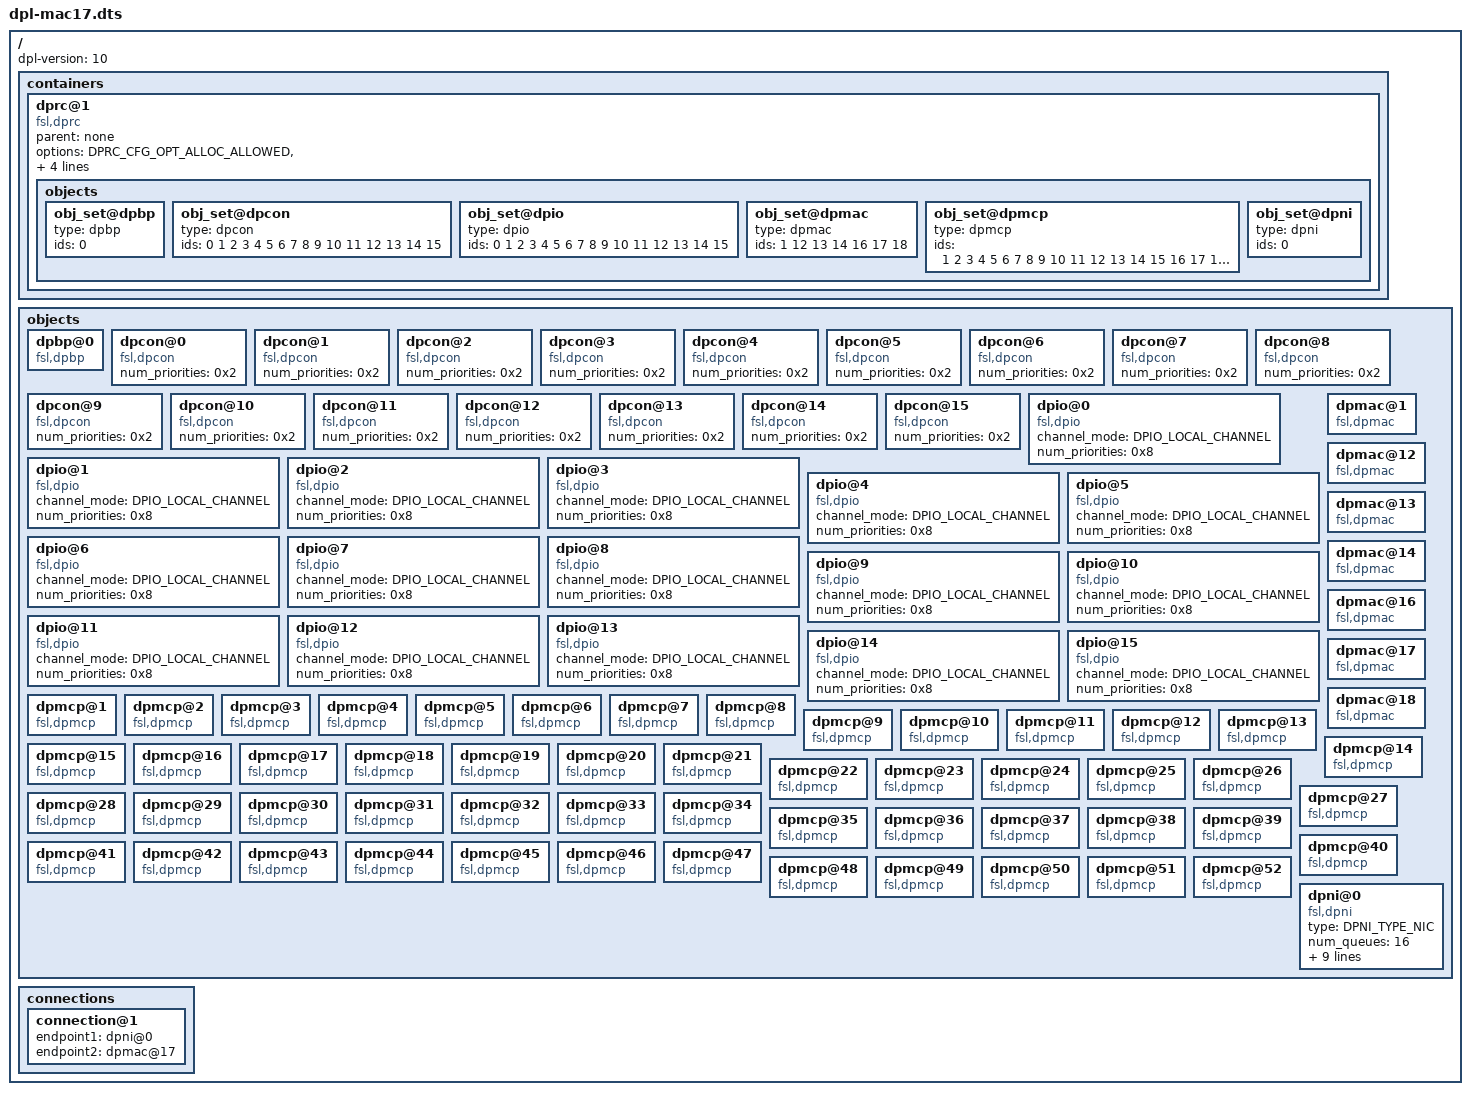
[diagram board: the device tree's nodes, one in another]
/* SPDX-License-Identifier: BSD-3-Clause */
/*
 * Copyright (c) 2024 TQ-Systems GmbH <oss@ew.tq-group.com>
 * D-82229 Seefeld, Germany.
 * Author: Gregor Herburger
 *
 */

/dts-v1/;
/ {
	dpl-version = <10>;
	/*****************************************************************
	 * Containers
	 *****************************************************************/
	containers {

		dprc@1 {
			compatible = "fsl,dprc";
			parent = "none";
			options = "DPRC_CFG_OPT_ALLOC_ALLOWED",
				  "DPRC_CFG_OPT_IRQ_CFG_ALLOWED",
				  "DPRC_CFG_OPT_OBJ_CREATE_ALLOWED",
				  "DPRC_CFG_OPT_SPAWN_ALLOWED",
				  "DPRC_CFG_OPT_TOPOLOGY_CHANGES_ALLOWED";

			objects {

				/* -------------- DPBPs --------------*/
				obj_set@dpbp {
					type = "dpbp";
					ids = <0 >;
				};

				/* -------------- DPCONs --------------*/
				obj_set@dpcon {
					type = "dpcon";
					ids = <0 1 2 3 4 5 6 7 8 9 10 11 12 13 14 15 >;
				};

				/* -------------- DPIOs --------------*/
				obj_set@dpio {
					type = "dpio";
					ids = <0 1 2 3 4 5 6 7 8 9 10 11 12 13 14 15 >;
				};

				/* -------------- DPMACs --------------*/
				obj_set@dpmac {
					type = "dpmac";
					ids = <1 12 13 14 16 17 18 >;
				};

				/* -------------- DPMCPs --------------*/
				obj_set@dpmcp {
					type = "dpmcp";
					ids = <
						1 2 3 4 5 6 7 8 9 10 11 12 13 14 15
						16 17 18 19 20 21 22 23 24 25 26 27
						28 29 30 31 32 33 34 35 36 37 38 39
						40 41 42 43 44 45 46 47 48 49 50 51 52
					      >;
				};

				/* -------------- DPNIs --------------*/
				obj_set@dpni {
					type = "dpni";
					ids = <0 >;
				};
			};
		};
	};

	/*****************************************************************
	 * Objects
	 *****************************************************************/
	objects {

		dpbp@0 {
			compatible = "fsl,dpbp";
		};

		dpcon@0 {
			compatible = "fsl,dpcon";
			num_priorities = <0x2>;
		};

		dpcon@1 {
			compatible = "fsl,dpcon";
			num_priorities = <0x2>;
		};

		dpcon@2 {
			compatible = "fsl,dpcon";
			num_priorities = <0x2>;
		};

		dpcon@3 {
			compatible = "fsl,dpcon";
			num_priorities = <0x2>;
		};

		dpcon@4 {
			compatible = "fsl,dpcon";
			num_priorities = <0x2>;
		};

		dpcon@5 {
			compatible = "fsl,dpcon";
			num_priorities = <0x2>;
		};

		dpcon@6 {
			compatible = "fsl,dpcon";
			num_priorities = <0x2>;
		};

		dpcon@7 {
			compatible = "fsl,dpcon";
			num_priorities = <0x2>;
		};

		dpcon@8 {
			compatible = "fsl,dpcon";
			num_priorities = <0x2>;
		};

		dpcon@9 {
			compatible = "fsl,dpcon";
			num_priorities = <0x2>;
		};

		dpcon@10 {
			compatible = "fsl,dpcon";
			num_priorities = <0x2>;
		};

		dpcon@11 {
			compatible = "fsl,dpcon";
			num_priorities = <0x2>;
		};

		dpcon@12 {
			compatible = "fsl,dpcon";
			num_priorities = <0x2>;
		};

		dpcon@13 {
			compatible = "fsl,dpcon";
			num_priorities = <0x2>;
		};

		dpcon@14 {
			compatible = "fsl,dpcon";
			num_priorities = <0x2>;
		};

		dpcon@15 {
			compatible = "fsl,dpcon";
			num_priorities = <0x2>;
		};

		dpio@0 {
			compatible = "fsl,dpio";
			channel_mode = "DPIO_LOCAL_CHANNEL";
			num_priorities = <0x8>;
		};

		dpio@1 {
			compatible = "fsl,dpio";
			channel_mode = "DPIO_LOCAL_CHANNEL";
			num_priorities = <0x8>;
		};

		dpio@2 {
			compatible = "fsl,dpio";
			channel_mode = "DPIO_LOCAL_CHANNEL";
			num_priorities = <0x8>;
		};

		dpio@3 {
			compatible = "fsl,dpio";
			channel_mode = "DPIO_LOCAL_CHANNEL";
			num_priorities = <0x8>;
		};

		dpio@4 {
			compatible = "fsl,dpio";
			channel_mode = "DPIO_LOCAL_CHANNEL";
			num_priorities = <0x8>;
		};

		dpio@5 {
			compatible = "fsl,dpio";
			channel_mode = "DPIO_LOCAL_CHANNEL";
			num_priorities = <0x8>;
		};

		dpio@6 {
			compatible = "fsl,dpio";
			channel_mode = "DPIO_LOCAL_CHANNEL";
			num_priorities = <0x8>;
		};

		dpio@7 {
			compatible = "fsl,dpio";
			channel_mode = "DPIO_LOCAL_CHANNEL";
			num_priorities = <0x8>;
		};

		dpio@8 {
			compatible = "fsl,dpio";
			channel_mode = "DPIO_LOCAL_CHANNEL";
			num_priorities = <0x8>;
		};

		dpio@9 {
			compatible = "fsl,dpio";
			channel_mode = "DPIO_LOCAL_CHANNEL";
			num_priorities = <0x8>;
		};

		dpio@10 {
			compatible = "fsl,dpio";
			channel_mode = "DPIO_LOCAL_CHANNEL";
			num_priorities = <0x8>;
		};

		dpio@11 {
			compatible = "fsl,dpio";
			channel_mode = "DPIO_LOCAL_CHANNEL";
			num_priorities = <0x8>;
		};

		dpio@12 {
			compatible = "fsl,dpio";
			channel_mode = "DPIO_LOCAL_CHANNEL";
			num_priorities = <0x8>;
		};

		dpio@13 {
			compatible = "fsl,dpio";
			channel_mode = "DPIO_LOCAL_CHANNEL";
			num_priorities = <0x8>;
		};

		dpio@14 {
			compatible = "fsl,dpio";
			channel_mode = "DPIO_LOCAL_CHANNEL";
			num_priorities = <0x8>;
		};

		dpio@15 {
			compatible = "fsl,dpio";
			channel_mode = "DPIO_LOCAL_CHANNEL";
			num_priorities = <0x8>;
		};

		dpmac@1 {
			compatible = "fsl,dpmac";
		};

		dpmac@12 {
			compatible = "fsl,dpmac";
		};

		dpmac@13 {
			compatible = "fsl,dpmac";
		};

		dpmac@14 {
			compatible = "fsl,dpmac";
		};

		dpmac@16 {
			compatible = "fsl,dpmac";
		};

		dpmac@17 {
			compatible = "fsl,dpmac";
		};

		dpmac@18 {
			compatible = "fsl,dpmac";
		};

		dpmcp@1 {
			compatible = "fsl,dpmcp";
		};

		dpmcp@2 {
			compatible = "fsl,dpmcp";
		};

		dpmcp@3 {
			compatible = "fsl,dpmcp";
		};

		dpmcp@4 {
			compatible = "fsl,dpmcp";
		};

		dpmcp@5 {
			compatible = "fsl,dpmcp";
		};

		dpmcp@6 {
			compatible = "fsl,dpmcp";
		};

		dpmcp@7 {
			compatible = "fsl,dpmcp";
		};

		dpmcp@8 {
			compatible = "fsl,dpmcp";
		};

		dpmcp@9 {
			compatible = "fsl,dpmcp";
		};

		dpmcp@10 {
			compatible = "fsl,dpmcp";
		};

		dpmcp@11 {
			compatible = "fsl,dpmcp";
		};

		dpmcp@12 {
			compatible = "fsl,dpmcp";
		};

		dpmcp@13 {
			compatible = "fsl,dpmcp";
		};

		dpmcp@14 {
			compatible = "fsl,dpmcp";
		};

		dpmcp@15 {
			compatible = "fsl,dpmcp";
		};

		dpmcp@16 {
			compatible = "fsl,dpmcp";
		};

		dpmcp@17 {
			compatible = "fsl,dpmcp";
		};

		dpmcp@18 {
			compatible = "fsl,dpmcp";
		};

		dpmcp@19 {
			compatible = "fsl,dpmcp";
		};

		dpmcp@20 {
			compatible = "fsl,dpmcp";
		};

		dpmcp@21 {
			compatible = "fsl,dpmcp";
		};

		dpmcp@22 {
			compatible = "fsl,dpmcp";
		};

		dpmcp@23 {
			compatible = "fsl,dpmcp";
		};

		dpmcp@24 {
			compatible = "fsl,dpmcp";
		};

		dpmcp@25 {
			compatible = "fsl,dpmcp";
		};

		dpmcp@26 {
			compatible = "fsl,dpmcp";
		};

		dpmcp@27 {
			compatible = "fsl,dpmcp";
		};

		dpmcp@28 {
			compatible = "fsl,dpmcp";
		};

		dpmcp@29 {
			compatible = "fsl,dpmcp";
		};

		dpmcp@30 {
			compatible = "fsl,dpmcp";
		};

		dpmcp@31 {
			compatible = "fsl,dpmcp";
		};

		dpmcp@32 {
			compatible = "fsl,dpmcp";
		};

		dpmcp@33 {
			compatible = "fsl,dpmcp";
		};

		dpmcp@34 {
			compatible = "fsl,dpmcp";
		};

		dpmcp@35 {
			compatible = "fsl,dpmcp";
		};

		dpmcp@36 {
			compatible = "fsl,dpmcp";
		};

		dpmcp@37 {
			compatible = "fsl,dpmcp";
		};

		dpmcp@38 {
			compatible = "fsl,dpmcp";
		};

		dpmcp@39 {
			compatible = "fsl,dpmcp";
		};

		dpmcp@40 {
			compatible = "fsl,dpmcp";
		};

		dpmcp@41 {
			compatible = "fsl,dpmcp";
		};

		dpmcp@42 {
			compatible = "fsl,dpmcp";
		};

		dpmcp@43 {
			compatible = "fsl,dpmcp";
		};

		dpmcp@44 {
			compatible = "fsl,dpmcp";
		};

		dpmcp@45 {
			compatible = "fsl,dpmcp";
		};

		dpmcp@46 {
			compatible = "fsl,dpmcp";
		};

		dpmcp@47 {
			compatible = "fsl,dpmcp";
		};

		dpmcp@48 {
			compatible = "fsl,dpmcp";
		};

		dpmcp@49 {
			compatible = "fsl,dpmcp";
		};

		dpmcp@50 {
			compatible = "fsl,dpmcp";
		};

		dpmcp@51 {
			compatible = "fsl,dpmcp";
		};

		dpmcp@52 {
			compatible = "fsl,dpmcp";
		};

		dpni@0 {
			compatible = "fsl,dpni";
			type = "DPNI_TYPE_NIC";
			num_queues = <16>;
			num_tcs = <1>;
			num_cgs = <1>;
			mac_filter_entries = <16>;
			vlan_filter_entries = <0>;
			fs_entries = <64>;
			qos_entries = <0>;
			dist_key_size = <56>;
			num_channels= <1>;
			num_opr = <0>;
		};
	};

	/*****************************************************************
	 * Connections
	 *****************************************************************/
	connections {

		connection@1{
			endpoint1 = "dpni@0";
			endpoint2 = "dpmac@17";
		};
	};
};
